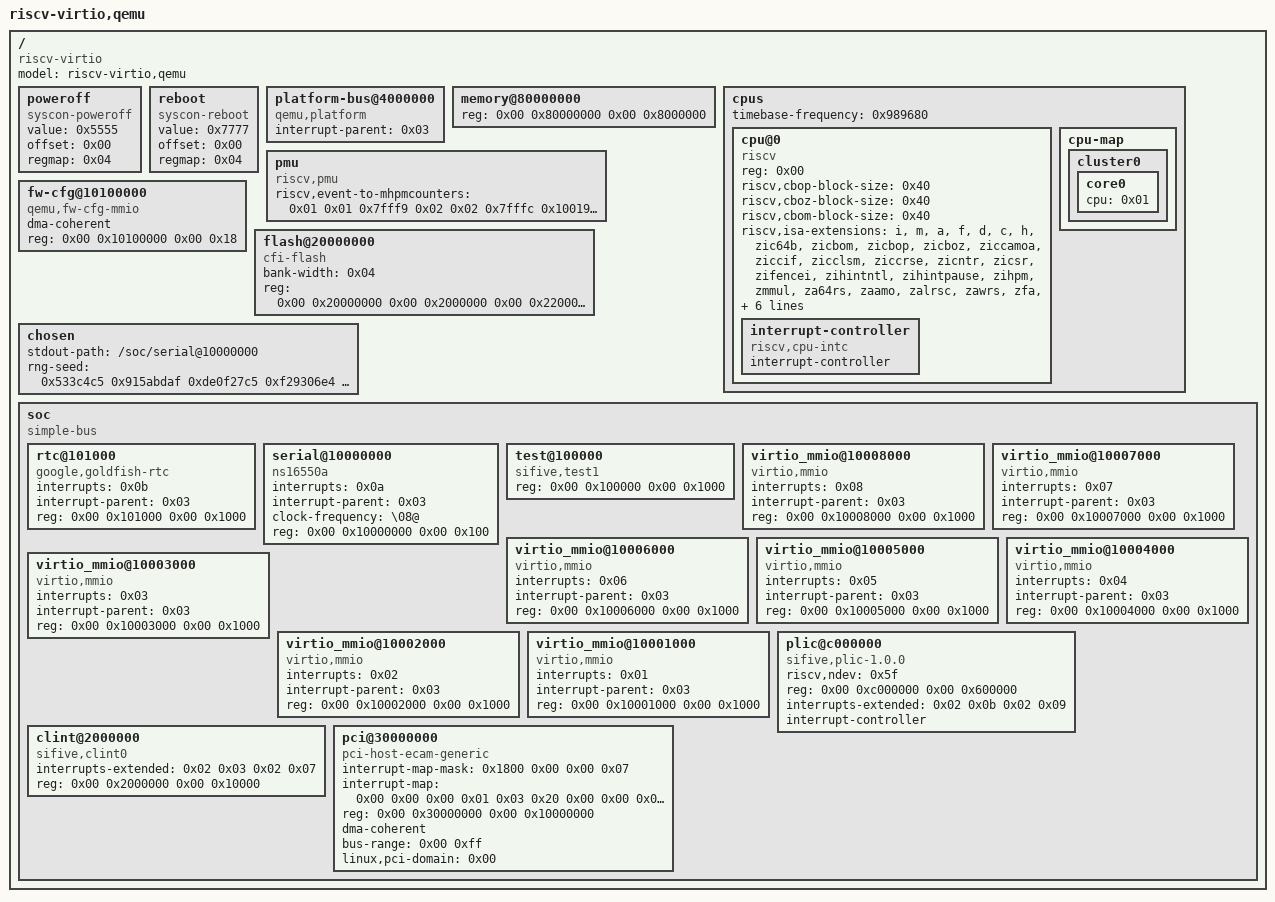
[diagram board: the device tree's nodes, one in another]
/// this file is a device tree source file, which is used to describe the hardware structure of the virtual machine

/dts-v1/;// 版本信息, 一定要定义的

/ {
	#address-cells = <0x02>;
	#size-cells = <0x02>;
	compatible = "riscv-virtio";
	model = "riscv-virtio,qemu";
	
	poweroff {
		value = <0x5555>;
		offset = <0x00>;
		regmap = <0x04>;
		compatible = "syscon-poweroff";
	};
	
	reboot {
		value = <0x7777>;
		offset = <0x00>;
		regmap = <0x04>;
		compatible = "syscon-reboot";
	};
	
	platform-bus@4000000 {
		interrupt-parent = <0x03>;
		ranges = <0x00 0x00 0x4000000 0x2000000>;
		#address-cells = <0x01>;
		#size-cells = <0x01>;
		compatible = "qemu,platform", "simple-bus";
	};
	
	memory@80000000 {
		device_type = "memory";
		reg = <0x00 0x80000000 0x00 0x8000000>;
	};
	
	// 描述 cpu, 只能是 cpus
	cpus {
		#address-cells = <0x01>;
		#size-cells = <0x00>;
		timebase-frequency = <0x989680>;
		
		cpu@0 {
			phandle = <0x01>;
			device_type = "cpu";
			reg = <0x00>;// addr: 0x00, size: 0x00
			status = "okay";
			compatible = "riscv";
			// 这一些是: 自定义的属性
			riscv,cbop-block-size = <0x40>;
			riscv,cboz-block-size = <0x40>;
			riscv,cbom-block-size = <0x40>;
			riscv,isa-extensions = "i","m","a","f","d","c","h","zic64b","zicbom","zicbop","zicboz","ziccamoa","ziccif","zicclsm","ziccrse","zicntr","zicsr","zifencei","zihintntl","zihintpause","zihpm","zmmul","za64rs","zaamo","zalrsc","zawrs","zfa","zca","zcd","zba","zbb","zbc","zbs","ssccptr","sscounterenw","sstc","sstvala","sstvecd","svadu";
			riscv,isa-base = "rv64i";
			riscv,isa = "rv64imafdch_zic64b_zicbom_zicbop_zicboz_ziccamoa_ziccif_zicclsm_ziccrse_zicntr_zicsr_zifencei_zihintntl_zihintpause_zihpm_zmmul_za64rs_zaamo_zalrsc_zawrs_zfa_zca_zcd_zba_zbb_zbc_zbs_ssccptr_sscounterenw_sstc_sstvala_sstvecd_svadu";
			mmu-type = "riscv,sv57";
			
			interrupt-controller {// 这是定义了一个 名为 interrupt-controller 的节点
				#interrupt-cells = <0x01>;
				interrupt-controller;
				compatible = "riscv,cpu-intc";
				phandle = <0x02>;
			};
		};
		
		
		// cpu-map 的父节点, 只能是 cpus
		// 主要用在描述: 大小核
		cpu-map {
			// cpu-map 下面可以有两个节点: 集群 cluster 和 socket
			// socket 节点描述的是: 主板上的 cpu 插槽, 有几个 socket 就表示有几个插槽
			
			cluster0 {// s7
				
				core0 {
					cpu = <0x01>;
					// 线程节点
					// thread0 // 因为现在的许多 cpu 都支持超线程
					// thread1
					// ...
				};
				
				// core1 
				// core2
				// ...
			};
			
			// 4 个 u7
		};
		
	};
	
	pmu {
		riscv,event-to-mhpmcounters = <0x01 0x01 0x7fff9 0x02 0x02 0x7fffc 0x10019 0x10019 0x7fff8 0x1001b 0x1001b 0x7fff8 0x10021 0x10021 0x7fff8>;
		compatible = "riscv,pmu";
	};
	
	fw-cfg@10100000 {
		dma-coherent;
		reg = <0x00 0x10100000 0x00 0x18>;
		compatible = "qemu,fw-cfg-mmio";
	};
	
	flash@20000000 {
		bank-width = <0x04>;
		reg = <0x00 0x20000000 0x00 0x2000000 0x00 0x22000000 0x00 0x2000000>;
		compatible = "cfi-flash";
	};
	
	chosen {
		stdout-path = "/soc/serial@10000000";
		rng-seed = <0x533c4c5 0x915abdaf 0xde0f27c5 0xf29306e4 0x3eb7fa09 0x6a7a0996 0xc6190868 0xe3aa25a9>;
	};
	
	soc {
		#address-cells = <0x02>;
		#size-cells = <0x02>;
		compatible = "simple-bus";
		ranges;
		
		rtc@101000 {
			interrupts = <0x0b>;
			interrupt-parent = <0x03>;
			reg = <0x00 0x101000 0x00 0x1000>;
			compatible = "google,goldfish-rtc";
		};
		
		serial@10000000 {
			interrupts = <0x0a>;  // 中断号
			interrupt-parent = <0x03>; // plic
			clock-frequency = "\08@";
			reg = <0x00 0x10000000 0x00 0x100>;  // < base, size >
			compatible = "ns16550a";
		};
		
		test@100000 {
			phandle = <0x04>;
			reg = <0x00 0x100000 0x00 0x1000>;
			compatible = "sifive,test1\0sifive,test0\0syscon";
		};
		
		virtio_mmio@10008000 {
			interrupts = <0x08>;
			interrupt-parent = <0x03>;
			reg = <0x00 0x10008000 0x00 0x1000>;
			compatible = "virtio,mmio";
		};
		
		virtio_mmio@10007000 {
			interrupts = <0x07>;
			interrupt-parent = <0x03>;
			reg = <0x00 0x10007000 0x00 0x1000>;
			compatible = "virtio,mmio";
		};
		
		virtio_mmio@10006000 {
			interrupts = <0x06>;
			interrupt-parent = <0x03>;
			reg = <0x00 0x10006000 0x00 0x1000>;
			compatible = "virtio,mmio";
		};
		
		virtio_mmio@10005000 {
			interrupts = <0x05>;
			interrupt-parent = <0x03>;
			reg = <0x00 0x10005000 0x00 0x1000>;
			compatible = "virtio,mmio";
		};
		
		virtio_mmio@10004000 {
			interrupts = <0x04>;
			interrupt-parent = <0x03>;
			reg = <0x00 0x10004000 0x00 0x1000>;
			compatible = "virtio,mmio";
		};
		
		virtio_mmio@10003000 {
			interrupts = <0x03>;
			interrupt-parent = <0x03>;
			reg = <0x00 0x10003000 0x00 0x1000>;
			compatible = "virtio,mmio";
		};
		
		virtio_mmio@10002000 {
			interrupts = <0x02>;
			interrupt-parent = <0x03>;
			reg = <0x00 0x10002000 0x00 0x1000>;
			compatible = "virtio,mmio";
		};
		
		virtio_mmio@10001000 {
			interrupts = <0x01>;
			interrupt-parent = <0x03>;
			reg = <0x00 0x10001000 0x00 0x1000>;
			compatible = "virtio,mmio";
		};
		
		plic@c000000 {
			phandle = <0x03>;
			riscv,ndev = <0x5f>;  // 支持 0x5f 个设备
			reg = <0x00 0xc000000 0x00 0x600000>; // (base, len) < 基地址, 大小 >
			// 这个 0x02 对应于 /cpus/cpu@0/interrupt-controller
			// 0x0b -> machine external interrupt , 0x09 -> supervisor external interrupt
			interrupts-extended = <0x02 0x0b 0x02 0x09>;  // (中断源, 中断号)
			interrupt-controller;  // annotate this node as an interrupt controller
			compatible = "sifive,plic-1.0.0\0riscv,plic0";
			#address-cells = <0x00>;  // 定义子节点地址部分的单元数。在 PLIC 节点下，通常不需要地址映射，因此设置为 0
			#interrupt-cells = <0x01>;  // 指向 plic 的 interrupts-cell 的数量
		};
		
		clint@2000000 {
			interrupts-extended = <0x02 0x03 0x02 0x07>;
			reg = <0x00 0x2000000 0x00 0x10000>;
			compatible = "sifive,clint0","riscv,clint0";
		};
		
		pci@30000000 {
			interrupt-map-mask = <0x1800 0x00 0x00 0x07>;
			interrupt-map = <0x00 0x00 0x00 0x01 0x03 0x20 0x00 0x00 0x00 0x02 0x03 0x21 0x00 0x00 0x00 0x03 0x03 0x22 0x00 0x00 0x00 0x04 0x03 0x23 0x800 0x00 0x00 0x01 0x03 0x21 0x800 0x00 0x00 0x02 0x03 0x22 0x800 0x00 0x00 0x03 0x03 0x23 0x800 0x00 0x00 0x04 0x03 0x20 0x1000 0x00 0x00 0x01 0x03 0x22 0x1000 0x00 0x00 0x02 0x03 0x23 0x1000 0x00 0x00 0x03 0x03 0x20 0x1000 0x00 0x00 0x04 0x03 0x21 0x1800 0x00 0x00 0x01 0x03 0x23 0x1800 0x00 0x00 0x02 0x03 0x20 0x1800 0x00 0x00 0x03 0x03 0x21 0x1800 0x00 0x00 0x04 0x03 0x22>;
			ranges = <0x1000000 0x00 0x00 0x00 0x3000000 0x00 0x10000 0x2000000 0x00 0x40000000 0x00 0x40000000 0x00 0x40000000 0x3000000 0x04 0x00 0x04 0x00 0x04 0x00>;
			reg = <0x00 0x30000000 0x00 0x10000000>;
			dma-coherent;
			bus-range = <0x00 0xff>;
			linux,pci-domain = <0x00>;
			device_type = "pci";
			compatible = "pci-host-ecam-generic";
			#size-cells = <0x02>;
			#interrupt-cells = <0x01>;
			#address-cells = <0x03>;
		};
	};
};
